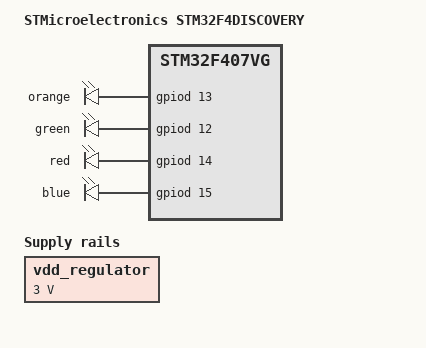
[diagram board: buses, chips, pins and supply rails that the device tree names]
/**
 * \file
 * \brief Devicetree for STM32F4DISCOVERY
 *
 * \author Copyright (C) 2017 Kamil Szczygiel http://www.distortec.com http://www.freddiechopin.info
 *
 * \par License
 * This Source Code Form is subject to the terms of the Mozilla Public License, v. 2.0. If a copy of the MPL was not
 * distributed with this file, You can obtain one at http://mozilla.org/MPL/2.0/.
 */

/dts-v1/;

#include "STM32F407VG.dtsi"

/ {
	compatible = "ST,STM32F4DISCOVERY", "ST,STM32F407VG";
	model = "STMicroelectronics STM32F4DISCOVERY";

	leds {
		compatible = "gpio-leds";
		status = "okay";

		ld3 {
			gpios = <&gpiod 13 0>;
			label = "orange";
			status = "okay";
		};

		ld4 {
			gpios = <&gpiod 12 0>;
			label = "green";
			status = "okay";
		};

		ld5 {
			gpios = <&gpiod 14 0>;
			label = "red";
			status = "okay";
		};

		ld6 {
			gpios = <&gpiod 15 0>;
			label = "blue";
			status = "okay";
		};
	};

	regulators {
		#address-cells = <1>;
		#size-cells = <0>;

		vdd_regulator: regulator@0 {
			compatible = "regulator-fixed";
			reg = <0>;
			regulator-name = "VDD";
			regulator-min-microvolt = <3000000>;
			regulator-max-microvolt = <3000000>;
			regulator-always-on;
		};
	};
};

&clock_hse {
	clock-frequency = <8000000>;
};

&gpioa {
	status = "okay";
};

&gpiod {
	status = "okay";
};
